AUTOSAR XML (schema 4-0-3)
package /MICROSAR/IoHwAb_swc/DataTypes
  impl type IOHWAB_BOOL: implementation-data-type=boolean
package /MICROSAR/IoHwAb_swc/Interfaces
  4 x client server interface:
    GetGpio_PortIf1
      operation Oper: possible-error=GetGpio_PortIf1/E_NOT_OK
        arg PinSt_Arg: type=IOHWAB_BOOL, direction=OUT
      error E_NOT_OK: error-code=1
    SetFctGpio_PortIf1
      operation Oper: possible-error=SetFctGpio_PortIf1/E_NOT_OK
      error E_NOT_OK: error-code=1
    SetFctPeriph_PortIf1
      operation Oper: possible-error=SetFctPeriph_PortIf1/E_NOT_OK
      error E_NOT_OK: error-code=1
    SetGpio_PortIf1
      operation Oper: possible-error=SetGpio_PortIf1/E_NOT_OK
        arg PinSt_Arg: type=IOHWAB_BOOL, direction=IN
      error E_NOT_OK: error-code=1
package /MICROSAR/IoHwAb_swc/ComponentTypes
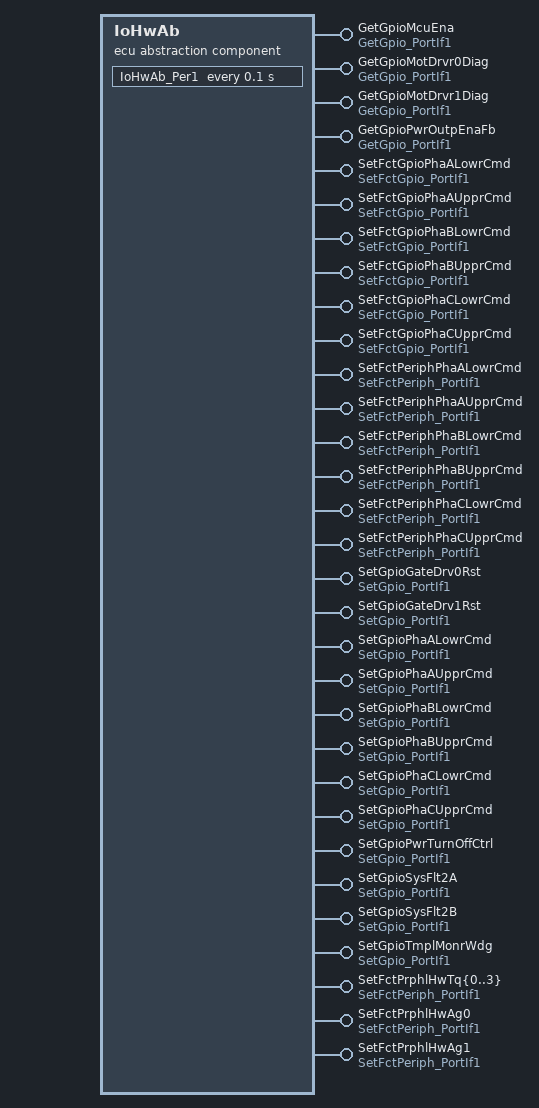
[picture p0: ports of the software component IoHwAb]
  ecu abstraction sw component type IoHwAb
    34 x provide port:
      GetGpioMcuEna: provided-interface=GetGpio_PortIf1
      GetGpioMotDrvr0Diag: provided-interface=GetGpio_PortIf1
      GetGpioMotDrvr1Diag: provided-interface=GetGpio_PortIf1
      GetGpioPwrOutpEnaFb: provided-interface=GetGpio_PortIf1
      SetFctGpioPhaALowrCmd: provided-interface=SetFctGpio_PortIf1
      SetFctGpioPhaAUpprCmd: provided-interface=SetFctGpio_PortIf1
      SetFctGpioPhaBLowrCmd: provided-interface=SetFctGpio_PortIf1
      SetFctGpioPhaBUpprCmd: provided-interface=SetFctGpio_PortIf1
      SetFctGpioPhaCLowrCmd: provided-interface=SetFctGpio_PortIf1
      SetFctGpioPhaCUpprCmd: provided-interface=SetFctGpio_PortIf1
      SetFctPeriphPhaALowrCmd: provided-interface=SetFctPeriph_PortIf1
      SetFctPeriphPhaAUpprCmd: provided-interface=SetFctPeriph_PortIf1
      SetFctPeriphPhaBLowrCmd: provided-interface=SetFctPeriph_PortIf1
      SetFctPeriphPhaBUpprCmd: provided-interface=SetFctPeriph_PortIf1
      SetFctPeriphPhaCLowrCmd: provided-interface=SetFctPeriph_PortIf1
      SetFctPeriphPhaCUpprCmd: provided-interface=SetFctPeriph_PortIf1
      SetGpioGateDrv0Rst: provided-interface=SetGpio_PortIf1
      SetGpioGateDrv1Rst: provided-interface=SetGpio_PortIf1
      SetGpioPhaALowrCmd: provided-interface=SetGpio_PortIf1
      SetGpioPhaAUpprCmd: provided-interface=SetGpio_PortIf1
      SetGpioPhaBLowrCmd: provided-interface=SetGpio_PortIf1
      SetGpioPhaBUpprCmd: provided-interface=SetGpio_PortIf1
      SetGpioPhaCLowrCmd: provided-interface=SetGpio_PortIf1
      SetGpioPhaCUpprCmd: provided-interface=SetGpio_PortIf1
      SetGpioPwrTurnOffCtrl: provided-interface=SetGpio_PortIf1
      SetGpioSysFlt2A: provided-interface=SetGpio_PortIf1
      SetGpioSysFlt2B: provided-interface=SetGpio_PortIf1
      SetGpioTmplMonrWdg: provided-interface=SetGpio_PortIf1
      SetFctPrphlHwTq{0..3}: provided-interface=SetFctPeriph_PortIf1
      SetFctPrphlHwAg0: provided-interface=SetFctPeriph_PortIf1
      SetFctPrphlHwAg1: provided-interface=SetFctPeriph_PortIf1
    behavior IoHwAbInternalBehavior: handle-termination-and-restart=NO-SUPPORT
      28 x operation invoked event:
        OpEventIoHwAb_GetGpioMcuEna_Oper_Oper_GetGpioMcuEna: start-on-event=IoHwAb_GetGpioMcuEna_Oper, operation=GetGpioMcuEna.Oper
        OpEventIoHwAb_GetGpioMotDrvr0Diag_Oper_Oper_GetGpioMotDrvr0Diag: start-on-event=IoHwAb_GetGpioMotDrvr0Diag_Oper, operation=GetGpioMotDrvr0Diag.Oper
        OpEventIoHwAb_GetGpioMotDrvr1Diag_Oper_Oper_GetGpioMotDrvr1Diag: start-on-event=IoHwAb_GetGpioMotDrvr1Diag_Oper, operation=GetGpioMotDrvr1Diag.Oper
        OpEventIoHwAb_GetGpioPwrOutpEnaFb_Oper_Oper_GetGpioPwrOutpEnaFb: start-on-event=IoHwAb_GetGpioPwrOutpEnaFb_Oper, operation=GetGpioPwrOutpEnaFb.Oper
        OpEventIoHwAb_SetFctGpioPhaALowrCmd_Oper_Oper_SetFctGpioPhaALowrCmd: start-on-event=IoHwAb_SetFctGpioPhaALowrCmd_Oper, operation=SetFctGpioPhaALowrCmd.Oper
        OpEventIoHwAb_SetFctGpioPhaAUpprCmd_Oper_Oper_SetFctGpioPhaAUpprCmd: start-on-event=IoHwAb_SetFctGpioPhaAUpprCmd_Oper, operation=SetFctGpioPhaAUpprCmd.Oper
        OpEventIoHwAb_SetFctGpioPhaBLowrCmd_Oper_Oper_SetFctGpioPhaBLowrCmd: start-on-event=IoHwAb_SetFctGpioPhaBLowrCmd_Oper, operation=SetFctGpioPhaBLowrCmd.Oper
        OpEventIoHwAb_SetFctGpioPhaBUpprCmd_Oper_Oper_SetFctGpioPhaBUpprCmd: start-on-event=IoHwAb_SetFctGpioPhaBUpprCmd_Oper, operation=SetFctGpioPhaBUpprCmd.Oper
        OpEventIoHwAb_SetFctGpioPhaCLowrCmd_Oper_Oper_SetFctGpioPhaCLowrCmd: start-on-event=IoHwAb_SetFctGpioPhaCLowrCmd_Oper, operation=SetFctGpioPhaCLowrCmd.Oper
        OpEventIoHwAb_SetFctGpioPhaCUpprCmd_Oper_Oper_SetFctGpioPhaCUpprCmd: start-on-event=IoHwAb_SetFctGpioPhaCUpprCmd_Oper, operation=SetFctGpioPhaCUpprCmd.Oper
        OpEventIoHwAb_SetFctPeriphPhaALowrCmd_Oper_Oper_SetFctPeriphPhaALowrCmd: start-on-event=IoHwAb_SetFctPeriphPhaALowrCmd_Oper, operation=SetFctPeriphPhaALowrCmd.Oper
        OpEventIoHwAb_SetFctPeriphPhaAUpprCmd_Oper_Oper_SetFctPeriphPhaAUpprCmd: start-on-event=IoHwAb_SetFctPeriphPhaAUpprCmd_Oper, operation=SetFctPeriphPhaAUpprCmd.Oper
        OpEventIoHwAb_SetFctPeriphPhaBLowrCmd_Oper_Oper_SetFctPeriphPhaBLowrCmd: start-on-event=IoHwAb_SetFctPeriphPhaBLowrCmd_Oper, operation=SetFctPeriphPhaBLowrCmd.Oper
        OpEventIoHwAb_SetFctPeriphPhaBUpprCmd_Oper_Oper_SetFctPeriphPhaBUpprCmd: start-on-event=IoHwAb_SetFctPeriphPhaBUpprCmd_Oper, operation=SetFctPeriphPhaBUpprCmd.Oper
        OpEventIoHwAb_SetFctPeriphPhaCLowrCmd_Oper_Oper_SetFctPeriphPhaCLowrCmd: start-on-event=IoHwAb_SetFctPeriphPhaCLowrCmd_Oper, operation=SetFctPeriphPhaCLowrCmd.Oper
        OpEventIoHwAb_SetFctPeriphPhaCUpprCmd_Oper_Oper_SetFctPeriphPhaCUpprCmd: start-on-event=IoHwAb_SetFctPeriphPhaCUpprCmd_Oper, operation=SetFctPeriphPhaCUpprCmd.Oper
        OpEventIoHwAb_SetGpioGateDrv0Rst_Oper_Oper_SetGpioGateDrv0Rst: start-on-event=IoHwAb_SetGpioGateDrv0Rst_Oper, operation=SetGpioGateDrv0Rst.Oper
        OpEventIoHwAb_SetGpioGateDrv1Rst_Oper_Oper_SetGpioGateDrv1Rst: start-on-event=IoHwAb_SetGpioGateDrv1Rst_Oper, operation=SetGpioGateDrv1Rst.Oper
        OpEventIoHwAb_SetGpioPhaALowrCmd_Oper_Oper_SetGpioPhaALowrCmd: start-on-event=IoHwAb_SetGpioPhaALowrCmd_Oper, operation=SetGpioPhaALowrCmd.Oper
        OpEventIoHwAb_SetGpioPhaAUpprCmd_Oper_Oper_SetGpioPhaAUpprCmd: start-on-event=IoHwAb_SetGpioPhaAUpprCmd_Oper, operation=SetGpioPhaAUpprCmd.Oper
        OpEventIoHwAb_SetGpioPhaBLowrCmd_Oper_Oper_SetGpioPhaBLowrCmd: start-on-event=IoHwAb_SetGpioPhaBLowrCmd_Oper, operation=SetGpioPhaBLowrCmd.Oper
        OpEventIoHwAb_SetGpioPhaBUpprCmd_Oper_Oper_SetGpioPhaBUpprCmd: start-on-event=IoHwAb_SetGpioPhaBUpprCmd_Oper, operation=SetGpioPhaBUpprCmd.Oper
        OpEventIoHwAb_SetGpioPhaCLowrCmd_Oper_Oper_SetGpioPhaCLowrCmd: start-on-event=IoHwAb_SetGpioPhaCLowrCmd_Oper, operation=SetGpioPhaCLowrCmd.Oper
        OpEventIoHwAb_SetGpioPhaCUpprCmd_Oper_Oper_SetGpioPhaCUpprCmd: start-on-event=IoHwAb_SetGpioPhaCUpprCmd_Oper, operation=SetGpioPhaCUpprCmd.Oper
        OpEventIoHwAb_SetGpioPwrTurnOffCtrl_Oper_Oper_SetGpioPwrTurnOffCtrl: start-on-event=IoHwAb_SetGpioPwrTurnOffCtrl_Oper, operation=SetGpioPwrTurnOffCtrl.Oper
        OpEventIoHwAb_SetGpioSysFlt2A_Oper_Oper_SetGpioSysFlt2A: start-on-event=IoHwAb_SetGpioSysFlt2A_Oper, operation=SetGpioSysFlt2A.Oper
        OpEventIoHwAb_SetGpioSysFlt2B_Oper_Oper_SetGpioSysFlt2B: start-on-event=IoHwAb_SetGpioSysFlt2B_Oper, operation=SetGpioSysFlt2B.Oper
        OpEventIoHwAb_SetGpioTmplMonrWdg_Oper_Oper_SetGpioTmplMonrWdg: start-on-event=IoHwAb_SetGpioTmplMonrWdg_Oper, operation=SetGpioTmplMonrWdg.Oper
      timing event Timer_IoHwAb_Per1: start-on-event=IoHwAb_Per1, period=0.1
      6 x operation invoked event:
        OpEventIoHwAb_SetFctPrphlHwTq{0..3}_Oper_Oper_SetFctPrphlHwTq{0..3}: start-on-event=IoHwAb_SetFctPrphlHwTq{0..3}_Oper, operation=SetFctPrphlHwTq{0..3}.Oper
        OpEventIoHwAb_SetFctPrphlHwAg0_Oper_Oper_SetFctPrphlHwAg0: start-on-event=IoHwAb_SetFctPrphlHwAg0_Oper, operation=SetFctPrphlHwAg0.Oper
        OpEventIoHwAb_SetFctPrphlHwAg1_Oper_Oper_SetFctPrphlHwAg1: start-on-event=IoHwAb_SetFctPrphlHwAg1_Oper, operation=SetFctPrphlHwAg1.Oper
      port-api-options:
        enable-take-address=true, indirect-api=false, port=GetGpioMcuEna
        enable-take-address=true, indirect-api=false, port=GetGpioMotDrvr0Diag
        enable-take-address=true, indirect-api=false, port=GetGpioMotDrvr1Diag
        enable-take-address=true, indirect-api=false, port=GetGpioPwrOutpEnaFb
        enable-take-address=true, indirect-api=false, port=SetFctGpioPhaALowrCmd
        enable-take-address=true, indirect-api=false, port=SetFctGpioPhaAUpprCmd
        enable-take-address=true, indirect-api=false, port=SetFctGpioPhaBLowrCmd
        enable-take-address=true, indirect-api=false, port=SetFctGpioPhaBUpprCmd
        enable-take-address=true, indirect-api=false, port=SetFctGpioPhaCLowrCmd
        enable-take-address=true, indirect-api=false, port=SetFctGpioPhaCUpprCmd
        enable-take-address=true, indirect-api=false, port=SetFctPeriphPhaALowrCmd
        enable-take-address=true, indirect-api=false, port=SetFctPeriphPhaAUpprCmd
        enable-take-address=true, indirect-api=false, port=SetFctPeriphPhaBLowrCmd
        enable-take-address=true, indirect-api=false, port=SetFctPeriphPhaBUpprCmd
        enable-take-address=true, indirect-api=false, port=SetFctPeriphPhaCLowrCmd
        enable-take-address=true, indirect-api=false, port=SetFctPeriphPhaCUpprCmd
        enable-take-address=true, indirect-api=false, port=SetGpioGateDrv0Rst
        enable-take-address=true, indirect-api=false, port=SetGpioGateDrv1Rst
        enable-take-address=true, indirect-api=false, port=SetGpioPhaALowrCmd
        enable-take-address=true, indirect-api=false, port=SetGpioPhaAUpprCmd
        enable-take-address=true, indirect-api=false, port=SetGpioPhaBLowrCmd
        enable-take-address=true, indirect-api=false, port=SetGpioPhaBUpprCmd
        enable-take-address=true, indirect-api=false, port=SetGpioPhaCLowrCmd
        enable-take-address=true, indirect-api=false, port=SetGpioPhaCUpprCmd
        enable-take-address=true, indirect-api=false, port=SetGpioPwrTurnOffCtrl
        enable-take-address=true, indirect-api=false, port=SetGpioSysFlt2A
        enable-take-address=true, indirect-api=false, port=SetGpioSysFlt2B
        enable-take-address=true, indirect-api=false, port=SetGpioTmplMonrWdg
        enable-take-address=true, indirect-api=false, port=SetFctPrphlHwTq{0..3}
        enable-take-address=true, indirect-api=false, port=SetFctPrphlHwAg0
        enable-take-address=true, indirect-api=false, port=SetFctPrphlHwAg1
      35 x runnable, all with can-be-invoked-concurrently=true:
        IoHwAb_GetGpioMcuEna_Oper  # Runnable Entity for calling the Operation 'Oper' of the Client/Server Port Prototype 'GetGpioMcuEna'.
        IoHwAb_GetGpioMotDrvr0Diag_Oper  # Runnable Entity for calling the Operation 'Oper' of the Client/Server Port Prototype 'GetGpioMotDrvr0Diag'.
        IoHwAb_GetGpioMotDrvr1Diag_Oper  # Runnable Entity for calling the Operation 'Oper' of the Client/Server Port Prototype 'GetGpioMotDrvr1Diag'.
        IoHwAb_GetGpioPwrOutpEnaFb_Oper  # Runnable Entity for calling the Operation 'Oper' of the Client/Server Port Prototype 'GetGpioPwrOutpEnaFb'.
        IoHwAb_SetFctGpioPhaALowrCmd_Oper  # Runnable Entity for calling the Operation 'Oper' of the Client/Server Port Prototype 'SetFctGpioPhaALowrCmd'.
        IoHwAb_SetFctGpioPhaAUpprCmd_Oper  # Runnable Entity for calling the Operation 'Oper' of the Client/Server Port Prototype 'SetFctGpioPhaAUpprCmd'.
        IoHwAb_SetFctGpioPhaBLowrCmd_Oper  # Runnable Entity for calling the Operation 'Oper' of the Client/Server Port Prototype 'SetFctGpioPhaBLowrCmd'.
        IoHwAb_SetFctGpioPhaBUpprCmd_Oper  # Runnable Entity for calling the Operation 'Oper' of the Client/Server Port Prototype 'SetFctGpioPhaBUpprCmd'.
        IoHwAb_SetFctGpioPhaCLowrCmd_Oper  # Runnable Entity for calling the Operation 'Oper' of the Client/Server Port Prototype 'SetFctGpioPhaCLowrCmd'.
        IoHwAb_SetFctGpioPhaCUpprCmd_Oper  # Runnable Entity for calling the Operation 'Oper' of the Client/Server Port Prototype 'SetFctGpioPhaCUpprCmd'.
        IoHwAb_SetFctPeriphPhaALowrCmd_Oper  # Runnable Entity for calling the Operation 'Oper' of the Client/Server Port Prototype 'SetFctPeriphPhaALowrCmd'.
        IoHwAb_SetFctPeriphPhaAUpprCmd_Oper  # Runnable Entity for calling the Operation 'Oper' of the Client/Server Port Prototype 'SetFctPeriphPhaAUpprCmd'.
        IoHwAb_SetFctPeriphPhaBLowrCmd_Oper  # Runnable Entity for calling the Operation 'Oper' of the Client/Server Port Prototype 'SetFctPeriphPhaBLowrCmd'.
        IoHwAb_SetFctPeriphPhaBUpprCmd_Oper  # Runnable Entity for calling the Operation 'Oper' of the Client/Server Port Prototype 'SetFctPeriphPhaBUpprCmd'.
        IoHwAb_SetFctPeriphPhaCLowrCmd_Oper  # Runnable Entity for calling the Operation 'Oper' of the Client/Server Port Prototype 'SetFctPeriphPhaCLowrCmd'.
        IoHwAb_SetFctPeriphPhaCUpprCmd_Oper  # Runnable Entity for calling the Operation 'Oper' of the Client/Server Port Prototype 'SetFctPeriphPhaCUpprCmd'.
        IoHwAb_SetGpioGateDrv0Rst_Oper  # Runnable Entity for calling the Operation 'Oper' of the Client/Server Port Prototype 'SetGpioGateDrv0Rst'.
        IoHwAb_SetGpioGateDrv1Rst_Oper  # Runnable Entity for calling the Operation 'Oper' of the Client/Server Port Prototype 'SetGpioGateDrv1Rst'.
        IoHwAb_SetGpioPhaALowrCmd_Oper  # Runnable Entity for calling the Operation 'Oper' of the Client/Server Port Prototype 'SetGpioPhaALowrCmd'.
        IoHwAb_SetGpioPhaAUpprCmd_Oper  # Runnable Entity for calling the Operation 'Oper' of the Client/Server Port Prototype 'SetGpioPhaAUpprCmd'.
        IoHwAb_SetGpioPhaBLowrCmd_Oper  # Runnable Entity for calling the Operation 'Oper' of the Client/Server Port Prototype 'SetGpioPhaBLowrCmd'.
        IoHwAb_SetGpioPhaBUpprCmd_Oper  # Runnable Entity for calling the Operation 'Oper' of the Client/Server Port Prototype 'SetGpioPhaBUpprCmd'.
        IoHwAb_SetGpioPhaCLowrCmd_Oper  # Runnable Entity for calling the Operation 'Oper' of the Client/Server Port Prototype 'SetGpioPhaCLowrCmd'.
        IoHwAb_SetGpioPhaCUpprCmd_Oper  # Runnable Entity for calling the Operation 'Oper' of the Client/Server Port Prototype 'SetGpioPhaCUpprCmd'.
        IoHwAb_SetGpioPwrTurnOffCtrl_Oper  # Runnable Entity for calling the Operation 'Oper' of the Client/Server Port Prototype 'SetGpioPwrTurnOffCtrl'.
        IoHwAb_SetGpioSysFlt2A_Oper  # Runnable Entity for calling the Operation 'Oper' of the Client/Server Port Prototype 'SetGpioSysFlt2A'.
        IoHwAb_SetGpioSysFlt2B_Oper  # Runnable Entity for calling the Operation 'Oper' of the Client/Server Port Prototype 'SetGpioSysFlt2B'.
        IoHwAb_SetGpioTmplMonrWdg_Oper  # Runnable Entity for calling the Operation 'Oper' of the Client/Server Port Prototype 'SetGpioTmplMonrWdg'.
        IoHwAb_Per1
        IoHwAb_SetFctPrphlHwTq{0..3}_Oper  # Runnable Entity for calling the Operation 'Oper' of the Client/Server Port Prototype 'SetFctPrphlHwTq{0..3}'.
        IoHwAb_SetFctPrphlHwAg0_Oper  # Runnable Entity for calling the Operation 'Oper' of the Client/Server Port Prototype 'SetFctPrphlHwAg0'.
        IoHwAb_SetFctPrphlHwAg1_Oper  # Runnable Entity for calling the Operation 'Oper' of the Client/Server Port Prototype 'SetFctPrphlHwAg1'.
  swc implementation IoHwAbImplementation: programming-language=C, behavior=IoHwAbInternalBehavior
